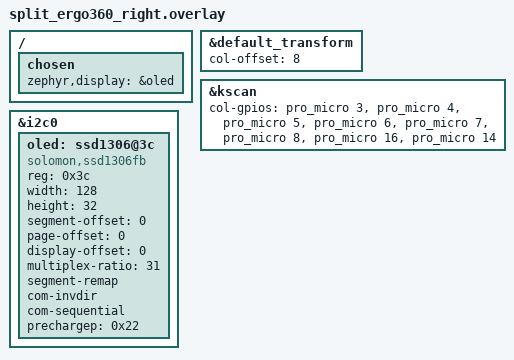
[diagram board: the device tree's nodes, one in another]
// This file was generated from a template. Edit it to match your keyboard.
// See https://zmk.dev/docs/development/hardware-integration/new-shield for more
// instructions.

#include "split_ergo360.dtsi"

&default_transform {
    // Set this to the number of columns on the left side.
    col-offset = <8>;
};

&kscan {
    // Replace these comments with the GPIO pins in the matrix for the right side.
    // See https://zmk.dev/docs/development/hardware-integration/new-shield#shield-overlays
    col-gpios
        = <&pro_micro 3 GPIO_ACTIVE_HIGH>
        , <&pro_micro 4 GPIO_ACTIVE_HIGH>
        , <&pro_micro 5 GPIO_ACTIVE_HIGH>
        , <&pro_micro 6 GPIO_ACTIVE_HIGH>
        , <&pro_micro 7 GPIO_ACTIVE_HIGH>
        , <&pro_micro 8 GPIO_ACTIVE_HIGH>
        , <&pro_micro 16 GPIO_ACTIVE_HIGH>
        , <&pro_micro 14 GPIO_ACTIVE_HIGH>
        ;
};

&i2c0 {
    status = "okay";
    
    oled: ssd1306@3c {
        compatible = "solomon,ssd1306fb";
        reg = <0x3c>;
        width = <128>;
        height = <32>;
        segment-offset = <0>;
        page-offset = <0>;
        display-offset = <0>;
        multiplex-ratio = <31>;
        segment-remap;
        com-invdir;
        com-sequential;
        prechargep = <0x22>;
    };
};

/ {
    chosen {
        zephyr,display = &oled;
    };
};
